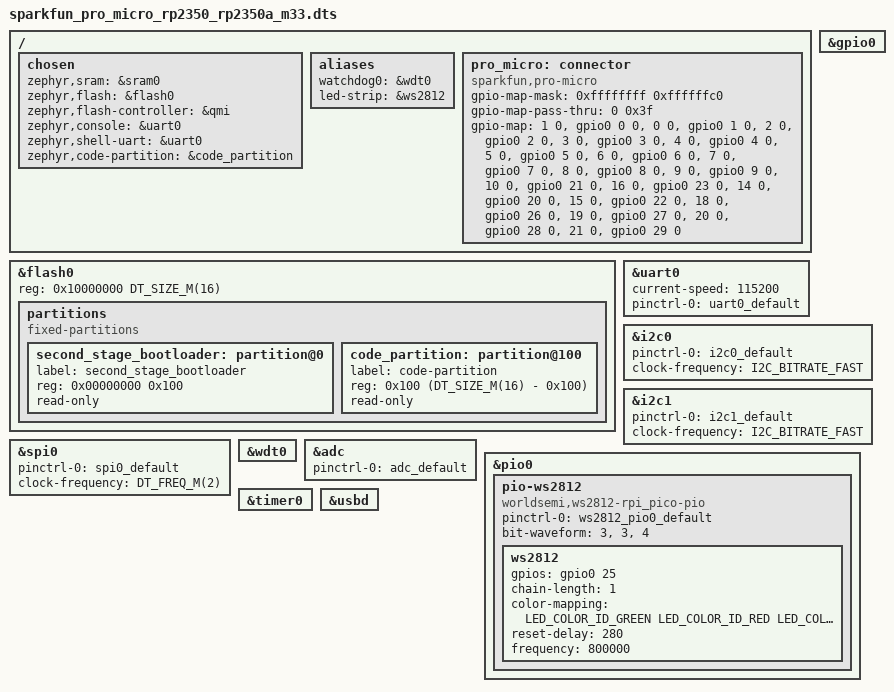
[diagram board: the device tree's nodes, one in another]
/*
 * Copyright (c) 2021 Yonatan Schachter
 *
 * SPDX-License-Identifier: Apache-2.0
 */

/dts-v1/;

#include <raspberrypi/rpi_pico/rp2350a.dtsi>
#include <raspberrypi/rpi_pico/m33.dtsi>

#include <freq.h>
#include "sparkfun_pro_micro_rp2350-pinctrl.dtsi"
/* #include <zephyr/dt-bindings/gpio/arduino-header-r3.h> */
#include <zephyr/dt-bindings/i2c/i2c.h>
#include <zephyr/dt-bindings/led/led.h>
#include <zephyr/dt-bindings/pwm/pwm.h>
#include <zephyr/dt-bindings/led/led.h>

/ {
	chosen {
		zephyr,sram = &sram0;
		zephyr,flash = &flash0;
		zephyr,flash-controller = &qmi;
		zephyr,console = &uart0;
		zephyr,shell-uart = &uart0;
		zephyr,code-partition = &code_partition;
	};

	aliases {
		watchdog0 = &wdt0;
		led-strip = &ws2812;
	};

	pro_micro: connector {
		compatible = "sparkfun,pro-micro";
		#gpio-cells = <2>;
		gpio-map-mask = <0xffffffff 0xffffffc0>;
		gpio-map-pass-thru = <0 0x3f>;
		gpio-map
			= <1 0 &gpio0 0 0>		/* D1 */
			, <0 0 &gpio0 1 0>		/* D0 */
			, <2 0 &gpio0 2 0>		/* D2 */
			, <3 0 &gpio0 3 0>		/* D3 */
			, <4 0 &gpio0 4 0>		/* D4/A6 */
			, <5 0 &gpio0 5 0>		/* D5 */
			, <6 0 &gpio0 6 0>		/* D6/A7 */
			, <7 0 &gpio0 7 0>		/* D7 */
			, <8 0 &gpio0 8 0>		/* D8/A8 */
			, <9 0 &gpio0 9 0>		/* D9/A9 */
			, <10 0 &gpio0 21 0>		/* D10/A10 */
			, <16 0 &gpio0 23 0>	/* D16 */
			, <14 0 &gpio0 20 0>	/* D14 */
			, <15 0 &gpio0 22 0>	/* D15 */
			, <18 0 &gpio0 26 0>	/* D18/A0 */
			, <19 0 &gpio0 27 0>	/* D19/A1 */
			, <20 0 &gpio0 28 0>	/* D20/A2 */
			, <21 0 &gpio0 29 0>	/* D21/A3 */
			;
	};
};

&flash0 {
	/* 16MB of flash minus the 0x100 used for
	 * the second stage bootloader
	 */
	reg = <0x10000000 DT_SIZE_M(16)>;

	partitions {
		compatible = "fixed-partitions";
		#address-cells = <1>;
		#size-cells = <1>;

		/* Reserved memory for the second stage bootloader */
		second_stage_bootloader: partition@0 {
			label = "second_stage_bootloader";
			reg = <0x00000000 0x100>;
			read-only;
		};


		/*
		 * Usable flash. Starts at 0x100, after the bootloader. The partition
		 * size is 16MB minus the 0x100 bytes taken by the bootloader.
		 */
		code_partition: partition@100 {
			label = "code-partition";
			reg = <0x100 (DT_SIZE_M(16) - 0x100)>;
			read-only;
		};
	};
};

pro_micro_serial: &uart0 {
	current-speed = <115200>;
	status = "okay";
	pinctrl-0 = <&uart0_default>;
	pinctrl-names = "default";
};

&gpio0 {
	status = "okay";
};

zephyr_i2c: &i2c0 {
	status = "okay";
	pinctrl-0 = <&i2c0_default>;
	pinctrl-names = "default";
	clock-frequency = <I2C_BITRATE_FAST>;
};

pro_micro_i2c: &i2c1 {
	status = "okay";
	pinctrl-0 = <&i2c1_default>;
	pinctrl-names = "default";
	clock-frequency = <I2C_BITRATE_FAST>;
};

pro_micro_spi: &spi0 {
	status = "okay";
	pinctrl-0 = <&spi0_default>;
	pinctrl-names = "default";
	clock-frequency = <DT_FREQ_M(2)>;
};

&wdt0 {
	status = "okay";
};

&adc {
	status = "okay";
	pinctrl-0 = <&adc_default>;
	pinctrl-names = "default";
};

&pio0 {
	status = "okay";

	pio-ws2812 {
		compatible = "worldsemi,ws2812-rpi_pico-pio";
		status = "okay";
		pinctrl-0 = <&ws2812_pio0_default>;
		pinctrl-names = "default";
		bit-waveform = <3>, <3>, <4>;

		ws2812: ws2812 {
			status = "okay";
			gpios = <&gpio0 25 GPIO_ACTIVE_HIGH>;
			chain-length = <1>;
			color-mapping = <LED_COLOR_ID_GREEN
					 LED_COLOR_ID_RED
					 LED_COLOR_ID_BLUE>;
			reset-delay = <280>;
			frequency = <800000>;
		};
	};
};


&timer0 {
	status = "okay";
};

zephyr_udc0: &usbd {
	status = "okay";
};

/* &vreg { */
/* 	regulator-always-on; */
/* 	regulator-allowed-modes = <REGULATOR_RPI_PICO_MODE_NORMAL>; */
/* }; */
